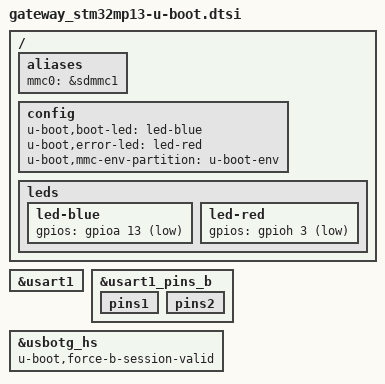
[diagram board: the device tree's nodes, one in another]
// SPDX-License-Identifier: GPL-2.0-or-later OR BSD-3-Clause
/*
 * Copyright (C) 2022, STMicroelectronics - All Rights Reserved
 */

#include "stm32mp13-u-boot.dtsi"

/ {
	aliases {
		mmc0 = &sdmmc1;
	};

	config {
		u-boot,boot-led = "led-blue";
		u-boot,error-led = "led-red";
		u-boot,mmc-env-partition = "u-boot-env";
	};

	leds {
		led-blue {
			/delete-property/default-state;
			gpios = <&gpioa 13 GPIO_ACTIVE_LOW>;
		};

		led-red {
			gpios = <&gpioh 3 GPIO_ACTIVE_LOW>;
		};
	};
};

&usart1 {
	bootph-all;
};

&usart1_pins_b {
	bootph-all;
	pins1 {
		bootph-all;
	};
	pins2 {
		bootph-all;
	};
};

&usbotg_hs {
	u-boot,force-b-session-valid;
};
